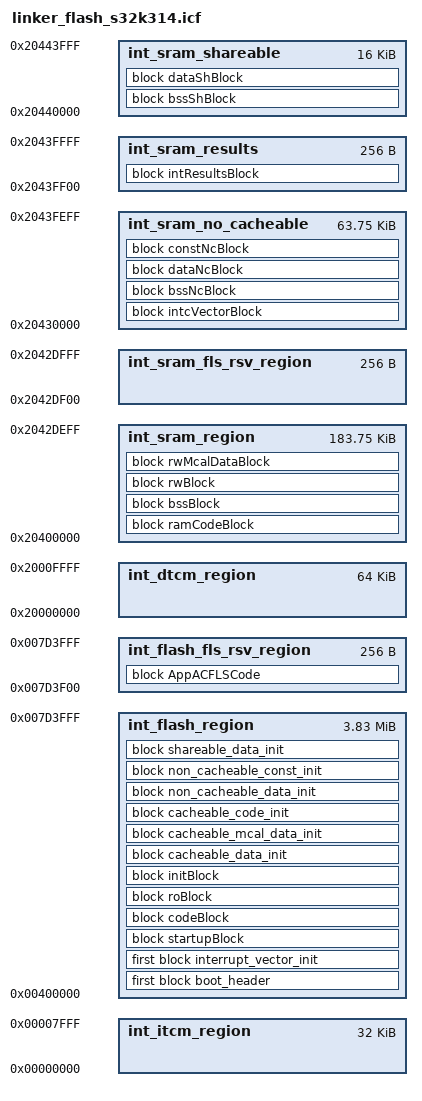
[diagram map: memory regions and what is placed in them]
/*==================================================================================================
*   Project              : RTD AUTOSAR 4.4
*   Platform             : CORTEXM
*   Peripheral           : 
*   Dependencies         : none
*
*   Autosar Version      : 4.4.0
*   Autosar Revision     : ASR_REL_4_4_REV_0000
*   Autosar Conf.Variant :
*   SW Version           : 2.0.1
*   Build Version        : S32K3_RTD_2_0_1_D2207_ASR_REL_4_4_REV_0000_20220707
*
*   (c) Copyright 2020 - 2022 NXP Semiconductors
*   All Rights Reserved.
*
*   NXP Confidential. This software is owned or controlled by NXP and may only be
*   used strictly in accordance with the applicable license terms. By expressly
*   accepting such terms or by downloading, installing, activating and/or otherwise
*   using the software, you are agreeing that you have read, and that you agree to
*   comply with and are bound by, such license terms. If you do not agree to be
*   bound by the applicable license terms, then you may not retain, install,
*   activate or otherwise use the software.
==================================================================================================*/
/*
* IAR Linker Command File:
* 0x00400000    0x007FFFFF  4194304 Program Flash (last 64K sBAF)
* 0x10000000    0x1003FFFF  262144  Data Flash (last 32K HSE_NVM)
* 0x20400000    0x20408000  32768   Standby RAM_0 (32K)
* 0x20400000    0x20427FFF  163840  SRAM_0
* 0x20428000    0x2044FFFF  163840  SRAM_1
* Last 48 KB of SRAM_1 reserved by HSE Firmware
* Last 176 KB of CODE_FLASH_3 reserved by HSE Firmware
* Last 128 KB of DATA_FLASH reserved by HSE Firmware (not supported in this linker file)
*/


define symbol int_flash_start              = 0x00400000;
define symbol int_flash_size               = 0x003D4000;    /* 4096K - 176K (sBAF + HSE) */


define symbol int_flash_fls_rsv_start      = 0x007D3F00;
define symbol int_flash_fls_rsv_size       = 0x00000100;    /* 256 byte for flash access code rom */

define symbol int_sram_start               = 0x20400000;
define symbol int_sram_size                = 0x0002DF00;    /* 183.9K */

define symbol int_itcm_start               = 0x00000000;
define symbol int_itcm_size                = 0x00008000;    /* 32K */

define symbol int_dtcm_start               = 0x20000000;
define symbol int_dtcm_size                = 0x00010000;    /* 64K */

define symbol int_sram_fls_rsv_start       = 0x2042DF00;
define symbol int_sram_fls_rsv_size        = 0x00000100;    /* 0.1K byte for flash access code ram */

define symbol int_sram_stack_c0_start      = 0x2042E000;
define symbol int_sram_stack_c0_size       = 0x00001000;    /* 4KB  */

define symbol int_sram_stack_c1_start      = 0x2042F000;
define symbol int_sram_stack_c1_size       = 0x00001000;    /* 4KB  */

define symbol int_sram_no_cacheable_start  = 0x20430000;
define symbol int_sram_no_cacheable_size   = 0x0000FF00;    /* 64KB, needs to include int_results  */

define symbol int_sram_results_start       = 0x2043FF00;
define symbol int_sram_results_size        = 0x00000100;    /* 64KB, needs to include int_results  */

define symbol int_sram_shareable_start     = 0x20440000;
define symbol int_sram_shareable_size      = 0x00004000;    /* 16KB */

define symbol ram_rsvd2                    = 0x20444000; 

define exported symbol __Stack_end_c0      = int_sram_stack_c0_start;
define exported symbol __Stack_start_c0    = int_sram_stack_c0_start + int_sram_stack_c0_size;  

define exported symbol __Stack_end_c1      = int_sram_stack_c1_start;
define exported symbol __Stack_start_c1    = int_sram_stack_c1_start + int_sram_stack_c1_size;  

define exported symbol __RAM_INIT          = 1;
define exported symbol __INT_SRAM_START    = int_sram_start;
define exported symbol __INT_SRAM_END      = ram_rsvd2;
define exported symbol __ITCM_INIT         = 1;
define exported symbol __INT_ITCM_START    = int_itcm_start;
define exported symbol __INT_ITCM_END      = int_itcm_start + int_itcm_size;
define exported symbol __DTCM_INIT         = 1;
define exported symbol __INT_DTCM_START    = int_dtcm_start;
define exported symbol __INT_DTCM_END      = int_dtcm_start + int_dtcm_size;
define exported symbol __RAM_NO_CACHEABLE_START      = int_sram_no_cacheable_start;

/* Fls module access code support */    
define exported symbol Fls_ACEraseRomStart  = int_flash_fls_rsv_start;
define exported symbol Fls_ACEraseRomEnd    = int_flash_fls_rsv_start + int_flash_fls_rsv_size ;
define exported symbol Fls_ACEraseSize      = int_flash_fls_rsv_size/4; /* Copy 4 bytes at a time*/ 

define exported symbol Fls_ACWriteRomStart  = int_flash_fls_rsv_start;
define exported symbol Fls_ACWriteRomEnd    = int_flash_fls_rsv_start + int_flash_fls_rsv_size ;
define exported symbol Fls_ACWriteSize      = int_flash_fls_rsv_size/4; /* Copy 4 bytes at a time*/ 

define exported symbol _ERASE_FUNC_ADDRESS_ = int_sram_fls_rsv_start;
define exported symbol _WRITE_FUNC_ADDRESS_ = int_sram_fls_rsv_start;

define memory mem with size = 4G;

define region int_flash_region        = mem:[from int_flash_start size int_flash_size];
define region int_flash_fls_rsv_region = mem:[from int_flash_fls_rsv_start size int_flash_fls_rsv_size];
define region int_sram_region         = mem:[from int_sram_start size int_sram_size];
define region int_sram_fls_rsv_region = mem:[from int_sram_fls_rsv_start size int_sram_fls_rsv_size];
define region int_sram_no_cacheable   = mem:[from int_sram_no_cacheable_start size int_sram_no_cacheable_size];
define region int_sram_results        = mem:[from int_sram_results_start size int_sram_results_size];
define region int_sram_shareable      = mem:[from int_sram_shareable_start size int_sram_shareable_size];
define region int_itcm_region         = mem:[from int_itcm_start size int_itcm_size];
define region int_dtcm_region         = mem:[from int_dtcm_start size int_dtcm_size];

initialize manually {
                     section .data, 
                     section .mcal_data, 
                     section .mcal_data_no_cacheable, 
                     section .mcal_shared_data, 
                     section .mcal_const_no_cacheable,
                     section .ramcode,
                     section .intvec
                    };

do not initialize { 
                    section .bss, 
                    section .mcal_bss, 
                    section .mcal_bss_no_cacheable, 
                    section .mcal_shared_bss,
                    section .data, 
                    section .mcal_data, 
                    section .mcal_data_no_cacheable, 
                    section .mcal_shared_data, 
                    section .mcal_const_no_cacheable, 
                    section .ramcode
                  };

/* Internal SRAM */
define block startupBlock with fixed order                  { section .core_loop, section .startup, section .systeminit };
define block codeBlock with fixed order                     { section .text, section .mcal_text, section .acmcu_code_rom };
define block AppACFLSCode with fixed order                  { section .acfls_code_rom};
define block roBlock with fixed order                       { section .rodata, section .mcal_const_cfg, section .mcal_const };
define block rwBlock with fixed order                       { section .data};
define block rwMcalDataBlock with fixed order               { section .mcal_data};
define block initBlock with fixed order                     { section .init_table, section .zero_table, section .iar.* };
define block ramCodeBlock with fixed order                  { section .ramcode };
define block bssBlock with fixed order, alignment = 64      { section .bss, section .mcal_bss };

/* Non cacheable */
define block intResultsBlock with fixed order, alignment = 4, size = 0x100 { section .intresult };
define block intcVectorBlock with fixed order, alignment = 4096            { section .intvec };
define block bssNcBlock with fixed order, alignment = 64                   { section .mcal_bss_no_cacheable };
define block dataNcBlock with fixed order                                  { section .mcal_data_no_cacheable };
define block constNcBlock with fixed order                                 { section .mcal_const_no_cacheable };

/* Shareable */
define block bssShBlock with fixed order, alignment = 64                   { section .mcal_shared_bss };
define block dataShBlock with fixed order                                  { section .mcal_shared_data };

/* Initialized data copy */
define block interrupt_vector_init with fixed order, alignment = 4096  { section .intvec_init };
define block cacheable_data_init with fixed order, alignment = 4       { section .data_init };
define block cacheable_mcal_data_init with fixed order, alignment = 4  { section .mcal_data_init };
define block cacheable_code_init with fixed order, alignment = 4       { section .ramcode_init };
define block non_cacheable_data_init with fixed order, alignment = 4   { section .mcal_data_no_cacheable_init };
define block non_cacheable_const_init with fixed order, alignment = 4  { section .mcal_const_no_cacheable_init };
define block shareable_data_init with fixed order, alignment = 4       { section .mcal_shared_data_init };

define block boot_header with fixed order, alignment = 4 { section .boot_header };

keep { block intResultsBlock, block intcVectorBlock, block boot_header };

place in int_flash_region      { first block boot_header };
place in int_flash_region      { first block interrupt_vector_init, block startupBlock, block codeBlock, block roBlock, block initBlock };
place in int_flash_region      { block cacheable_data_init, block cacheable_mcal_data_init, block cacheable_code_init, block non_cacheable_data_init, block non_cacheable_const_init, block shareable_data_init };
place in int_flash_fls_rsv_region { block AppACFLSCode};  
place in int_sram_region       { block ramCodeBlock, block bssBlock, block rwBlock, block rwMcalDataBlock};

place in int_sram_no_cacheable { block intcVectorBlock };
place in int_sram_no_cacheable { block bssNcBlock, block dataNcBlock, block constNcBlock};
place in int_sram_shareable    { block bssShBlock};
place in int_sram_shareable    { block dataShBlock};
place in int_sram_results { block intResultsBlock };

define exported symbol __ENTRY_VTABLE = start(int_flash_region) + 4096;
define exported symbol __CORE0_VTOR = start(int_flash_region) + 4096;
define exported symbol __CORE1_VTOR = start(int_flash_region) + 4096;

define exported symbol __ROM_DATA_START = 0x10000000;
define exported symbol __ROM_CODE_START = int_flash_start;
define exported symbol __RAM_SHAREABLE_START = int_sram_shareable_start;
define exported symbol __RAM_SHAREABLE_SIZE = 0xE; /*16 kbyte*/

define exported symbol __RAM_NO_CACHEABLE_SIZE = 0x10;  /* 64kbyte in power of 2 */
define exported symbol __RAM_CACHEABLE_SIZE = 0x12;  /* 256kbyte in power of 2 */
